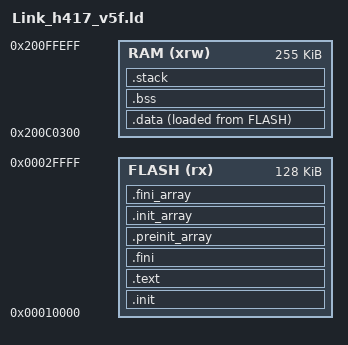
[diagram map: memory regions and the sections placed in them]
ENTRY(_start)

__stack_size = 4096;

MEMORY
{
    FLASH (rx) : ORIGIN = 0x00010000, LENGTH = 128K
    RAM (xrw) : ORIGIN = 0x200C0300, LENGTH = 255K
}

SECTIONS
{
    .init :
    {
        . = ALIGN(4);
        KEEP(*(.init))
        . = ALIGN(4);
    } >FLASH

    .text :
    {
        . = ALIGN(4);
        *(.text)
        *(.text.*)
        *(.rodata)
        *(.rodata*)
        *(.sdata2.*)
        *(.glue_7)
        *(.glue_7t)
        *(.gnu.linkonce.t.*)
        . = ALIGN(4);
    } >FLASH

    .fini :
    {
        KEEP(*(.fini))
        . = ALIGN(4);
    } >FLASH

    PROVIDE(_etext = .);

    .preinit_array :
    {
        PROVIDE_HIDDEN(__preinit_array_start = .);
        KEEP(*(.preinit_array))
        PROVIDE_HIDDEN(__preinit_array_end = .);
    } >FLASH

    .init_array :
    {
        PROVIDE_HIDDEN(__init_array_start = .);
        KEEP(*(SORT_BY_INIT_PRIORITY(.init_array.*) SORT_BY_INIT_PRIORITY(.ctors.*)))
        KEEP(*(.init_array EXCLUDE_FILE (*crtbegin.o *crtbegin?.o *crtend.o *crtend?.o) .ctors))
        PROVIDE_HIDDEN(__init_array_end = .);
    } >FLASH

    .fini_array :
    {
        PROVIDE_HIDDEN(__fini_array_start = .);
        KEEP(*(SORT_BY_INIT_PRIORITY(.fini_array.*) SORT_BY_INIT_PRIORITY(.dtors.*)))
        KEEP(*(.fini_array EXCLUDE_FILE (*crtbegin.o *crtbegin?.o *crtend.o *crtend?.o) .dtors))
        PROVIDE_HIDDEN(__fini_array_end = .);
    } >FLASH

    .data :
    {
        . = ALIGN(4);
        PROVIDE(_sdata = .);
        PROVIDE(_data_vma = .);
        *(.data)
        *(.data.*)
        *(.gnu.linkonce.d.*)
        . = ALIGN(8);
        PROVIDE(__global_pointer$ = . + 0x800);
        *(.sdata)
        *(.sdata.*)
        *(.gnu.linkonce.s.*)
        . = ALIGN(8);
        *(.srodata.cst16)
        *(.srodata.cst8)
        *(.srodata.cst4)
        *(.srodata.cst2)
        *(.srodata)
        *(.srodata.*)
        . = ALIGN(4);
        PROVIDE(_edata = .);
    } >RAM AT>FLASH

    PROVIDE(_data_lma = LOADADDR(.data));

    .bss :
    {
        . = ALIGN(4);
        PROVIDE(_sbss = .);
        *(.sbss*)
        *(.gnu.linkonce.sb.*)
        *(.bss*)
        *(.gnu.linkonce.b.*)
        *(COMMON*)
        . = ALIGN(4);
        PROVIDE(_ebss = .);
    } >RAM

    PROVIDE(_end = _ebss);
    PROVIDE(end = .);

    .stack ORIGIN(RAM) + LENGTH(RAM) - __stack_size :
    {
        PROVIDE(_heap_end = .);
        . = ALIGN(4);
        PROVIDE(_susrstack = .);
        . = . + __stack_size;
        PROVIDE(_eusrstack = .);
    } >RAM
}
